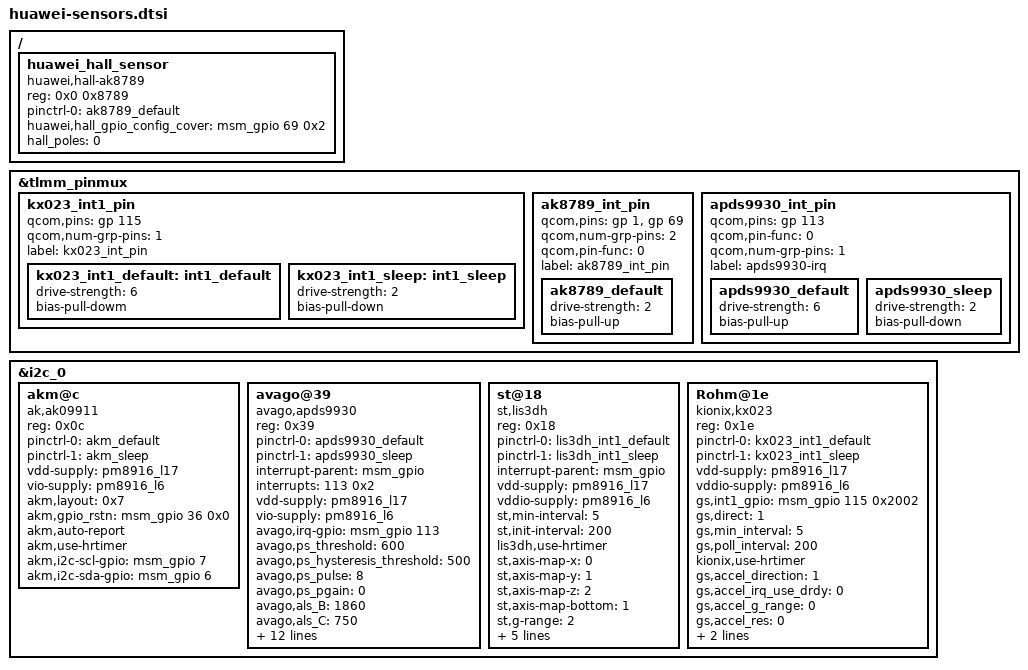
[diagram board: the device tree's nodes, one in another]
/* < DTS201505289999M zhujie 20150528 begin */
/*use fromdos convert file format to linux*/
/* Copyright (c) 2013 The Linux Foundation. All rights reserved.
 *
 * This program is free software; you can redistribute it and/or modify
 * it under the terms of the GNU General Public License version 2 and
 * only version 2 as published by the Free Software Foundation.
 *
 * This program is distributed in the hope that it will be useful,
 * but WITHOUT ANY WARRANTY; without even the implied warranty of
 * MERCHANTABILITY or FITNESS FOR A PARTICULAR PURPOSE.  See the
 * GNU General Public License for more details.
 */
&tlmm_pinmux {

	kx023_int1_pin {
		qcom,pins = <&gp 115>;
		qcom,num-grp-pins = <1>;
		label = "kx023_int_pin";
		kx023_int1_default: int1_default {
			  drive-strength = <6>;
			  bias-pull-dowm;
		};
		kx023_int1_sleep: int1_sleep {
			drive-strength = <2>;
			bias-pull-down;
		};
	};

	ak8789_int_pin {
		qcom,pins = <&gp 1>, <&gp 69>;
		qcom,num-grp-pins = <2>;
		qcom,pin-func = <0>;
		label = "ak8789_int_pin";
		ak8789_default: ak8789_default {
			  drive-strength = <2>;
			  bias-pull-up;
		};
	};
	apds9930_int_pin {
		qcom,pins = <&gp 113>;
		qcom,pin-func = <0>;
		qcom,num-grp-pins = <1>;
		label = "apds9930-irq";
		apds9930_default: apds9930_default {
			drive-strength = <6>;
			bias-pull-up;
		};
		apds9930_sleep: apds9930_sleep {
			drive-strength = <2>;
			bias-pull-down;
		};
	};
};

&i2c_0 { /* BLSP1 QUP2 */
	akm@c {
		compatible = "ak,ak09911";
		reg = <0x0c>;
		pinctrl-names = "default","sleep";
		pinctrl-0 = <&akm_default>;
		pinctrl-1 = <&akm_sleep>;
		vdd-supply = <&pm8916_l17>;
		vio-supply = <&pm8916_l6>;
		akm,layout = <0x7>;
		akm,gpio_rstn = <&msm_gpio 36 0x0>;
		akm,auto-report;
		akm,use-hrtimer;
		akm,i2c-scl-gpio = <&msm_gpio 7 0x0>;
		akm,i2c-sda-gpio = <&msm_gpio 6 0x0>;
	};

	avago@39 {
		compatible = "avago,apds9930";
		reg = <0x39>;
		pinctrl-names = "default","sleep";
		pinctrl-0 = <&apds9930_default>;
		pinctrl-1 = <&apds9930_sleep>;
		interrupt-parent = <&msm_gpio>;
		interrupts = <113 0x2>;
		vdd-supply = <&pm8916_l17>;
		vio-supply = <&pm8916_l6>;
		avago,irq-gpio = <&msm_gpio 113 0x2>;
		avago,ps_threshold = <600>;
		avago,ps_hysteresis_threshold = <500>;
		avago,ps_pulse = <8>;
		avago,ps_pgain = <0>;
		avago,als_B = <1860>;
		avago,als_C = <750>;
		avago,als_D = <1290>;
		avago,ga_value = <48>;
		avago,ga_a_value = <111>;
		avago,ga_c_value = <518>;
		avago,ga_d_value = <212>;
		avago,window = <161>;
		avago,wave = <58>;
		avago,ga_e_value = <220>;
		avago,ga_f_value = <43>;
		avago,i2c-scl-gpio = <&msm_gpio 7 0x0>;
		avago,i2c-sda-gpio = <&msm_gpio 6 0x0>;
		avago,mix-light;
	};

	st@18 {
		compatible = "st,lis3dh";
		reg = <0x18>;
		pinctrl-names = "lis3dh_default","lis3dh_sleep";
		pinctrl-0 = <&lis3dh_int1_default>;
		pinctrl-1 = <&lis3dh_int1_sleep>;
		interrupt-parent = <&msm_gpio>;
		vdd-supply = <&pm8916_l17>;
		vddio-supply = <&pm8916_l6>;
		st,min-interval = <5>;
		st,init-interval = <200>;
		lis3dh,use-hrtimer;
		st,axis-map-x = <0>;
		st,axis-map-y = <1>;
		st,axis-map-z = <2>;
		/*1 is bottom and others means top*/
		st,axis-map-bottom=<1>;
		st,g-range = <2>;
		st,gpio-int1 = <&msm_gpio 115 0x2002>;
		/delete-property/st,negate-x;
		st,negate-z;
		st,negate-y;
		st,i2c-scl-gpio = <&msm_gpio 7 0x0>;
		st,i2c-sda-gpio = <&msm_gpio 6 0x0>;
	};
	Rohm@1e {
		compatible = "kionix,kx023";
		reg = <0x1e>;
		pinctrl-names = "kx023_default","kx023_sleep";
		pinctrl-0 = <&kx023_int1_default>;
		pinctrl-1 = <&kx023_int1_sleep>;
		vdd-supply = <&pm8916_l17>;
		vddio-supply = <&pm8916_l6>;
		gs,int1_gpio = <&msm_gpio 115 0x2002>;
		gs,direct = <1>;
		gs,min_interval = <5>;
		gs,poll_interval = <200>;
		kionix,use-hrtimer;
		gs,accel_direction = <1>;
		gs,accel_irq_use_drdy = <0>;
		gs,accel_g_range = <0>;
		gs,accel_res = <0>;
		gs,i2c-scl-gpio = <&msm_gpio 7 0x0>;
		gs,i2c-sda-gpio = <&msm_gpio 6 0x0>;
	};
};
/{
	huawei_hall_sensor{
		compatible = "huawei,hall-ak8789";
		reg = <0x0 0x8789>;
		pinctrl-names = "default";
		pinctrl-0 = <&ak8789_default>;
		huawei,hall_gpio_config_cover = <&msm_gpio 69 0x2>;
		hall_poles = <0>;
		status = "ok";
	};
};
/* DTS201505289999M zhujie 20150528 end > */
